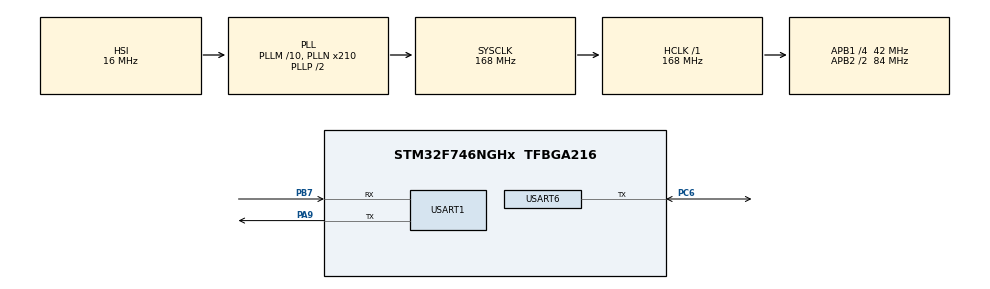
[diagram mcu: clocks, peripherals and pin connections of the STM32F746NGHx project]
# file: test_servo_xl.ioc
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Mcu.Family=STM32F7
Mcu.Name=STM32F746NGHx
Mcu.Package=TFBGA216
NVIC.PriorityGroup=NVIC_PRIORITYGROUP_4
PA13.Mode=Serial_Wire
PA13.Signal=SYS_JTMS-SWDIO
PA14.Mode=Serial_Wire
PA14.Signal=SYS_JTCK-SWCLK
PA9.Mode=Asynchronous
PA9.Signal=USART1_TX
PB7.Mode=Asynchronous
PB7.Signal=USART1_RX
PC6.GPIO_ModeDefaultOD=GPIO_MODE_AF_PP
PC6.GPIO_PuPd=GPIO_NOPULL
PC6.Mode=Half_duplex(single_wire_mode)
PC6.Signal=USART6_TX
PH0/OSC_IN.Mode=HSE-External-Oscillator
PH0/OSC_IN.Signal=RCC_OSC_IN
PH1/OSC_OUT.Mode=HSE-External-Oscillator
PH1/OSC_OUT.Signal=RCC_OSC_OUT
ProjectManager.HeapSize=0x200
ProjectManager.StackSize=0x400
ProjectManager.TargetToolchain=STM32CubeIDE
RCC.AHBFreq_Value=168000000
RCC.APB1CLKDivider=RCC_HCLK_DIV4
RCC.APB1Freq_Value=42000000
RCC.APB1TimFreq_Value=84000000
RCC.APB2CLKDivider=RCC_HCLK_DIV2
RCC.APB2Freq_Value=84000000
RCC.APB2TimFreq_Value=168000000
RCC.CortexFreq_Value=168000000
RCC.HCLKFreq_Value=168000000
RCC.HSE_VALUE=25000000
RCC.HSI_VALUE=16000000
RCC.LSE_VALUE=32768
RCC.PLLM=10
RCC.PLLN=210
RCC.PLLSourceVirtual=RCC_PLLSOURCE_HSI
RCC.SYSCLKFreq_VALUE=168000000
RCC.SYSCLKSource=RCC_SYSCLKSOURCE_PLLCLK
RCC.USBFreq_Value=168000000
RCC.VCOOutputFreq_Value=336000000
USART1.VirtualMode-Asynchronous=VM_ASYNC
USART6.BaudRate=1000000
USART6.VirtualMode-Half_duplex(single_wire_mode)=VM_ASYNC
board=STM32F746G-DISCO

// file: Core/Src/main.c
/* USER CODE BEGIN Header */
/**
 ******************************************************************************
 * @file           : main.c
 * @brief          : Main program body
 ******************************************************************************
 * @attention
 *
 * Copyright (c) 2022 STMicroelectronics.
 * All rights reserved.
 *
 * This software is licensed under terms that can be found in the LICENSE file
 * in the root directory of this software component.
 * If no LICENSE file comes with this software, it is provided AS-IS.
 *
 ******************************************************************************
 */
/* USER CODE END Header */
#include "main.h"
#include "usart.h"
#include "gpio.h"

/* USER CODE BEGIN Includes */
#include <stdio.h>
#include "xl320_driver.h"
/* USER CODE END Includes */

/* USER CODE BEGIN PV */
XL320_t xl320;
/* USER CODE END PV */

void SystemClock_Config(void);

/* USER CODE BEGIN 0 */

int __io_putchar(int ch)
{
	HAL_UART_Transmit(&huart1, (uint8_t *)&ch, 1, 0xFFFF);
	return ch;
}
void HAL_UART_RxCpltCallback(UART_HandleTypeDef *huart)
{

}
/* USER CODE END 0 */

int main(void)
{

	/* MCU Configuration--------------------------------------------------------*/

	/* Reset of all peripherals, Initializes the Flash interface and the Systick. */
	HAL_Init();

	/* Configure the system clock */
	SystemClock_Config();

	/* Initialize all configured peripherals */
	MX_GPIO_Init();
	MX_USART1_UART_Init();
	MX_USART6_UART_Init();
	/* USER CODE BEGIN 2 */
	xl320.serial.transmit = uart_half_duplex_transmit;
	xl320.serial.receive  = uart_half_duplex_receive;

	xl320_init(&xl320, 1, BR_1M);
	xl320_torqueEnable(&xl320);
	xl320_setSpeed(&xl320, 10);
	HAL_Delay(250);

	/* USER CODE END 2 */

	/* Infinite loop */
	/* USER CODE BEGIN WHILE */
	while (1)
	{
		/*
		xl320_setGoalPosition(&xl320, 69);
		xl320_executeAction(&xl320);
		HAL_Delay(1000);
		xl320_setGoalPosition(&xl320, 0);
		xl320_executeAction(&xl320);
		HAL_Delay(1000);
		 */

		xl320_ping(&xl320);
		HAL_Delay(2000);

		/* USER CODE END WHILE */

	}
}

void SystemClock_Config(void)
{
	RCC_OscInitTypeDef RCC_OscInitStruct = {0};
	RCC_ClkInitTypeDef RCC_ClkInitStruct = {0};

	/** Configure the main internal regulator output voltage
	 */
	__HAL_RCC_PWR_CLK_ENABLE();
	__HAL_PWR_VOLTAGESCALING_CONFIG(PWR_REGULATOR_VOLTAGE_SCALE2);

	/** Initializes the RCC Oscillators according to the specified parameters
	 * in the RCC_OscInitTypeDef structure.
	 */
	RCC_OscInitStruct.OscillatorType = RCC_OSCILLATORTYPE_HSI;
	RCC_OscInitStruct.HSIState = RCC_HSI_ON;
	RCC_OscInitStruct.HSICalibrationValue = RCC_HSICALIBRATION_DEFAULT;
	RCC_OscInitStruct.PLL.PLLState = RCC_PLL_ON;
	RCC_OscInitStruct.PLL.PLLSource = RCC_PLLSOURCE_HSI;
	RCC_OscInitStruct.PLL.PLLM = 10;
	RCC_OscInitStruct.PLL.PLLN = 210;
	RCC_OscInitStruct.PLL.PLLP = RCC_PLLP_DIV2;
	RCC_OscInitStruct.PLL.PLLQ = 2;
	if (HAL_RCC_OscConfig(&RCC_OscInitStruct) != HAL_OK)
	{
		Error_Handler();
	}

	/** Initializes the CPU, AHB and APB buses clocks
	 */
	RCC_ClkInitStruct.ClockType = RCC_CLOCKTYPE_HCLK|RCC_CLOCKTYPE_SYSCLK
			|RCC_CLOCKTYPE_PCLK1|RCC_CLOCKTYPE_PCLK2;
	RCC_ClkInitStruct.SYSCLKSource = RCC_SYSCLKSOURCE_PLLCLK;
	RCC_ClkInitStruct.AHBCLKDivider = RCC_SYSCLK_DIV1;
	RCC_ClkInitStruct.APB1CLKDivider = RCC_HCLK_DIV4;
	RCC_ClkInitStruct.APB2CLKDivider = RCC_HCLK_DIV2;

	if (HAL_RCC_ClockConfig(&RCC_ClkInitStruct, FLASH_LATENCY_5) != HAL_OK)
	{
		Error_Handler();
	}
}

void Error_Handler(void)
{
	__disable_irq();
	while (1)
	{
	}
}
